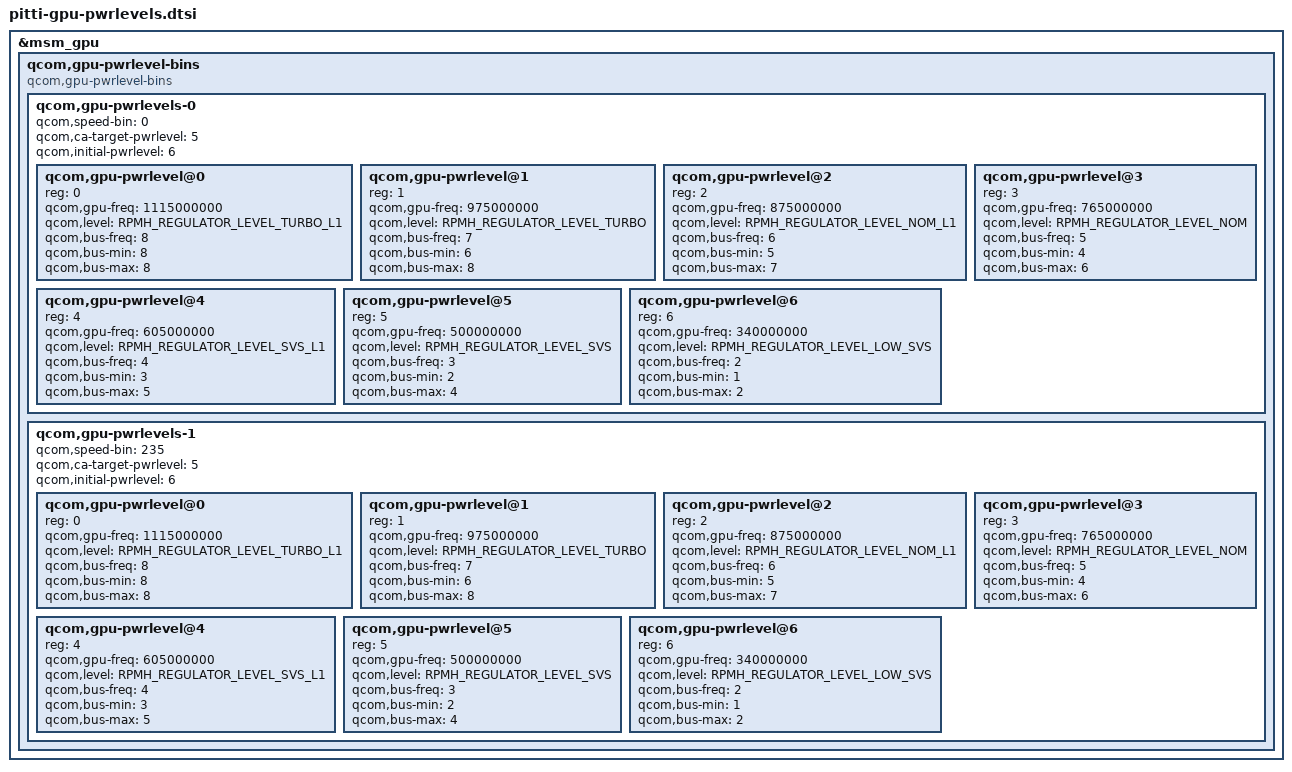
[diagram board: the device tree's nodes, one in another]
&msm_gpu {
	qcom,gpu-pwrlevel-bins {
		#address-cells = <1>;
		#size-cells = <0>;
		compatible = "qcom,gpu-pwrlevel-bins";

		qcom,gpu-pwrlevels-0 {
			#address-cells = <1>;
			#size-cells = <0>;

			qcom,speed-bin = <0>;

			qcom,ca-target-pwrlevel = <5>;
			qcom,initial-pwrlevel = <6>;

			/* TURBO_L1 */
			qcom,gpu-pwrlevel@0 {
				reg = <0>;
				qcom,gpu-freq = <1115000000>;
				qcom,level = <RPMH_REGULATOR_LEVEL_TURBO_L1>;

				qcom,bus-freq = <8>;
				qcom,bus-min = <8>;
				qcom,bus-max = <8>;
			};

			/* TURBO */
			qcom,gpu-pwrlevel@1 {
				reg = <1>;
				qcom,gpu-freq = <975000000>;
				qcom,level = <RPMH_REGULATOR_LEVEL_TURBO>;

				qcom,bus-freq = <7>;
				qcom,bus-min = <6>;
				qcom,bus-max = <8>;

			};

			/* NOM_L1 */
			qcom,gpu-pwrlevel@2 {
				reg = <2>;
				qcom,gpu-freq = <875000000>;
				qcom,level = <RPMH_REGULATOR_LEVEL_NOM_L1>;

				qcom,bus-freq = <6>;
				qcom,bus-min = <5>;
				qcom,bus-max = <7>;

			};

			/* NOM */
			qcom,gpu-pwrlevel@3 {
				reg = <3>;
				qcom,gpu-freq = <765000000>;
				qcom,level = <RPMH_REGULATOR_LEVEL_NOM>;

				qcom,bus-freq = <5>;
				qcom,bus-min = <4>;
				qcom,bus-max = <6>;

			};

			/* SVS_L1 */
			qcom,gpu-pwrlevel@4 {
				reg = <4>;
				qcom,gpu-freq = <605000000>;
				qcom,level = <RPMH_REGULATOR_LEVEL_SVS_L1>;

				qcom,bus-freq = <4>;
				qcom,bus-min = <3>;
				qcom,bus-max = <5>;

			};

			/* SVS */
			qcom,gpu-pwrlevel@5 {
				reg = <5>;
				qcom,gpu-freq = <500000000>;
				qcom,level = <RPMH_REGULATOR_LEVEL_SVS>;

				qcom,bus-freq = <3>;
				qcom,bus-min = <2>;
				qcom,bus-max = <4>;
			};

			/* LOW SVS */
			qcom,gpu-pwrlevel@6 {
				reg = <6>;
				qcom,gpu-freq = <340000000>;
				qcom,level = <RPMH_REGULATOR_LEVEL_LOW_SVS>;

				qcom,bus-freq = <2>;
				qcom,bus-min = <1>;
				qcom,bus-max = <2>;
			};

		};

		qcom,gpu-pwrlevels-1 {
			#address-cells = <1>;
			#size-cells = <0>;

			qcom,speed-bin = <235>;

			qcom,ca-target-pwrlevel = <5>;
			qcom,initial-pwrlevel = <6>;

			/* TURBO_L1 */
			qcom,gpu-pwrlevel@0 {
				reg = <0>;
				qcom,gpu-freq = <1115000000>;
				qcom,level = <RPMH_REGULATOR_LEVEL_TURBO_L1>;

				qcom,bus-freq = <8>;
				qcom,bus-min = <8>;
				qcom,bus-max = <8>;
			};

			/* TURBO */
			qcom,gpu-pwrlevel@1 {
				reg = <1>;
				qcom,gpu-freq = <975000000>;
				qcom,level = <RPMH_REGULATOR_LEVEL_TURBO>;

				qcom,bus-freq = <7>;
				qcom,bus-min = <6>;
				qcom,bus-max = <8>;

			};

			/* NOM_L1 */
			qcom,gpu-pwrlevel@2 {
				reg = <2>;
				qcom,gpu-freq = <875000000>;
				qcom,level = <RPMH_REGULATOR_LEVEL_NOM_L1>;

				qcom,bus-freq = <6>;
				qcom,bus-min = <5>;
				qcom,bus-max = <7>;

			};

			/* NOM */
			qcom,gpu-pwrlevel@3 {
				reg = <3>;
				qcom,gpu-freq = <765000000>;
				qcom,level = <RPMH_REGULATOR_LEVEL_NOM>;

				qcom,bus-freq = <5>;
				qcom,bus-min = <4>;
				qcom,bus-max = <6>;

			};

			/* SVS_L1 */
			qcom,gpu-pwrlevel@4 {
				reg = <4>;
				qcom,gpu-freq = <605000000>;
				qcom,level = <RPMH_REGULATOR_LEVEL_SVS_L1>;

				qcom,bus-freq = <4>;
				qcom,bus-min = <3>;
				qcom,bus-max = <5>;

			};

			/* SVS */
			qcom,gpu-pwrlevel@5 {
				reg = <5>;
				qcom,gpu-freq = <500000000>;
				qcom,level = <RPMH_REGULATOR_LEVEL_SVS>;

				qcom,bus-freq = <3>;
				qcom,bus-min = <2>;
				qcom,bus-max = <4>;
			};

			/* LOW SVS */
			qcom,gpu-pwrlevel@6 {
				reg = <6>;
				qcom,gpu-freq = <340000000>;
				qcom,level = <RPMH_REGULATOR_LEVEL_LOW_SVS>;

				qcom,bus-freq = <2>;
				qcom,bus-min = <1>;
				qcom,bus-max = <2>;
			};
		};
	};
};
